# PAC55XX register map
Vendor: Active-Semi; Series: PAC55XX; File version: 1.0
CPU: CM4 r0p1, little endian, MPU, FPU, vendor SysTick, 3 interrupt priority bits
Registers are 32-bit, read-write, reset 0x0 unless marked. A register's access mark holds for its fields unless they carry their own. Offsets are from the block's base; [hi:lo] are bit positions; {n}, {i} and the like mark numbered series.

## TimerB
Base 0x40070000
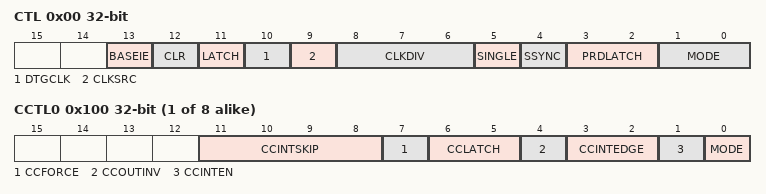
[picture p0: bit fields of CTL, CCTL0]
0x00 CTL — Timer B Control
  [13] BASEIE — Base timer interrupt enable
    0=Disabled (Base interrupt disabled); 1=Enabled (Base interrupt enabled)
  [12] CLR — Timer Clear
    0=Do not clear timer counter; 1=Clear timer counter
  [11] LATCH — Write 1 to Latch Period and all CCTRs
  [10] DTGCLK — Dead-Time Generator Clock Source
    0=Before Divider (Before input clock divider); 1=After Divider (After input clock divider)
  [9] CLKSRC — Timer Clock Source
    0=PCLK (PCLK selected as input to timer); 1=ACLK (ACLK selected as input to timer)
  [8:6] CLKDIV — Timer Input Clock Divider
    0=/1 (Timer input clock /1); 1=/2 (Timer input clock /2); 2=/4 (Timer input clock /4); 3=/8 (Timer input clock /8); 4=/16 (Timer input clock /16); 5=/32 (Timer input clock /32); 6=/64 (Timer input clock /64); 7=/128 (Timer input clock /128)
  [5] SINGLE — Single Shot Timer
    0=Disabled (Single Shot Disabled (auto-reload)); 1=Enabled (Single Shot Timer Enabled)
  [4] SSYNC — Timer Slave Synchronization
    0=Disabled (Slave Sync Disabled); 1=Enabled (Slave Sync Enabled)
  [3:2] PRDLATCH — Timer Period Latch Mode
    0=CTR=0 (Period is latched when CTR = 0); 1=CTR=Period (Period is latched when CTR = Period); 2=Immediate (Period is latched immediately upon register write)
  [1:0] MODE — Timer Mode
    0=Disabled Mode; 1=Up (Up Mode); 2=Up/Down Mode; 3=Asymmetric Mode
0x04 INT — Timer B Interrupt Control
0x08 PRD — Timer B Period
0x0C CTR — Timer B Counter
0x10 QEPCTL — Timer B QEP Control
{0x100+8i} CCTL{i} (i=0..7) — Timer B CC Control {i}
  [11:8] CCINTSKIP — CC Interrupt Skip Counter
    0=Don't skip CCR matches before interrupt; 1=Skip 1 CCR match before interrupt; {v}=Skip {v} CCR matches before interrupt (v=2..15)
  [7] CCFORCE — Write 1 to force compare event (self-clearing)
  [6:5] CCLATCH — CCR Register Latch Mode
    0=CTR=0/Rising (Compare(latch on CTR=0)/ Capture(latch on rising edge)); 1=CTR=Period/Falling (Compare(latch on CTR=Period)/ Capture(latch on falling edge)); 2=Immediate/Both (Compare(latch immediately)/ Capture(latch on both edges))
  [4] CCOUTINV — Invert CCR Output
    0=Not Inverted (Do not invert CCR output); 1=Inverted (Invert CCR output)
  [3:2] CCINTEDGE — Capture Mode Interrupt Edge Setting
    0=Rising Edge Interrupt; 1=Falling Edge Interrupt; 2=Both (Rising and Falling Edge Interrupt)
  [1] CCINTEN — CCR Interrupt Enable
    0=Disabled (CCR interrupt disabled); 1=Enabled (CCR interrupt enabled)
  [0] MODE — CCR Mode
    0=Compare Mode; 1=Capture Mode
{0x104+8i} CCTR{i} (i=0..7) — Timer B CC Counter {i}
{0x200+4i} DTGCTL{i} (i=0..3) — Timer B DTG Control {i}

## TimerC
Base 0x40080000
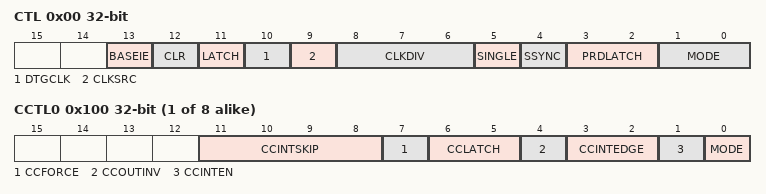
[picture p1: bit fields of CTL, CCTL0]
0x00 CTL — Timer C Control
  [13] BASEIE — Base timer interrupt enable
    0=Disabled (Base interrupt disabled); 1=Enabled (Base interrupt enabled)
  [12] CLR — Timer Clear
    0=Do not clear timer counter; 1=Clear timer counter
  [11] LATCH — Write 1 to Latch Period and all CCTRs
  [10] DTGCLK — Dead-Time Generator Clock Source
    0=Before Divider (Before input clock divider); 1=After Divider (After input clock divider)
  [9] CLKSRC — Timer Clock Source
    0=PCLK (PCLK selected as input to timer); 1=ACLK (ACLK selected as input to timer)
  [8:6] CLKDIV — Timer Input Clock Divider
    0=/1 (Timer input clock /1); 1=/2 (Timer input clock /2); 2=/4 (Timer input clock /4); 3=/8 (Timer input clock /8); 4=/16 (Timer input clock /16); 5=/32 (Timer input clock /32); 6=/64 (Timer input clock /64); 7=/128 (Timer input clock /128)
  [5] SINGLE — Single Shot Timer
    0=Disabled (Single Shot Disabled (auto-reload)); 1=Enabled (Single Shot Timer Enabled)
  [4] SSYNC — Timer Slave Synchronization
    0=Disabled (Slave Sync Disabled); 1=Enabled (Slave Sync Enabled)
  [3:2] PRDLATCH — Timer Period Latch Mode
    0=CTR=0 (Period is latched when CTR = 0); 1=CTR=Period (Period is latched when CTR = Period); 2=Immediate (Period is latched immediately upon register write)
  [1:0] MODE — Timer Mode
    0=Disabled Mode; 1=Up (Up Mode); 2=Up/Down Mode; 3=Asymmetric Mode
0x04 INT — Timer C Interrupt Control
0x08 PRD — Timer C Period
0x0C CTR — Timer C Counter
0x10 QEPCTL — Timer C QEP Control
{0x100+8i} CCTL{i} (i=0..7) — Timer C CC Control {i}
  [11:8] CCINTSKIP — CC Interrupt Skip Counter
    0=Don't skip CCR matches before interrupt; 1=Skip 1 CCR match before interrupt; {v}=Skip {v} CCR matches before interrupt (v=2..15)
  [7] CCFORCE — Write 1 to force compare event (self-clearing)
  [6:5] CCLATCH — CCR Register Latch Mode
    0=CTR=0/Rising (Compare(latch on CTR=0)/ Capture(latch on rising edge)); 1=CTR=Period/Falling (Compare(latch on CTR=Period)/ Capture(latch on falling edge)); 2=Immediate/Both (Compare(latch immediately)/ Capture(latch on both edges))
  [4] CCOUTINV — Invert CCR Output
    0=Not Inverted (Do not invert CCR output); 1=Inverted (Invert CCR output)
  [3:2] CCINTEDGE — Capture Mode Interrupt Edge Setting
    0=Rising Edge Interrupt; 1=Falling Edge Interrupt; 2=Both (Rising and Falling Edge Interrupt)
  [1] CCINTEN — CCR Interrupt Enable
    0=Disabled (CCR interrupt disabled); 1=Enabled (CCR interrupt enabled)
  [0] MODE — CCR Mode
    0=Compare Mode; 1=Capture Mode
{0x104+8i} CCTR{i} (i=0..7) — Timer C CC Counter {i}
{0x200+4i} DTGCTL{i} (i=0..3) — Timer C DTG Control {i}

## Notices in the file
Copyright (C) 2017 Active-Semi, Inc. All rights reserved.
THIS SOFTWARE IS SUBJECT TO A SOURCE CODE LICENSE AGREEMENT WHICH PROVIDES,
AMONG OTHER THINGS:  (i) THAT IT CAN BE USED ONLY TO ADAPT THE LICENSEE'S
APPLICATION TO PAC PROCESSORS SUPPLIED BY ACTIVE-SEMI INTERNATIONAL;
(ii) THAT  IT IS PROVIDED "AS IS" WITHOUT WARRANTY;  (iii) THAT
ACTIVE-SEMICONDUCTOR IS NOT LIABLE FOR ANY INDIRECT DAMAGES OR FOR DIRECT
DAMAGES EXCEEDING US$1,500;  AND (iv) THAT IT CAN BE DISCLOSED TO AND USED
ONLY BY CERTAIN AUTHORIZED PERSONS.
